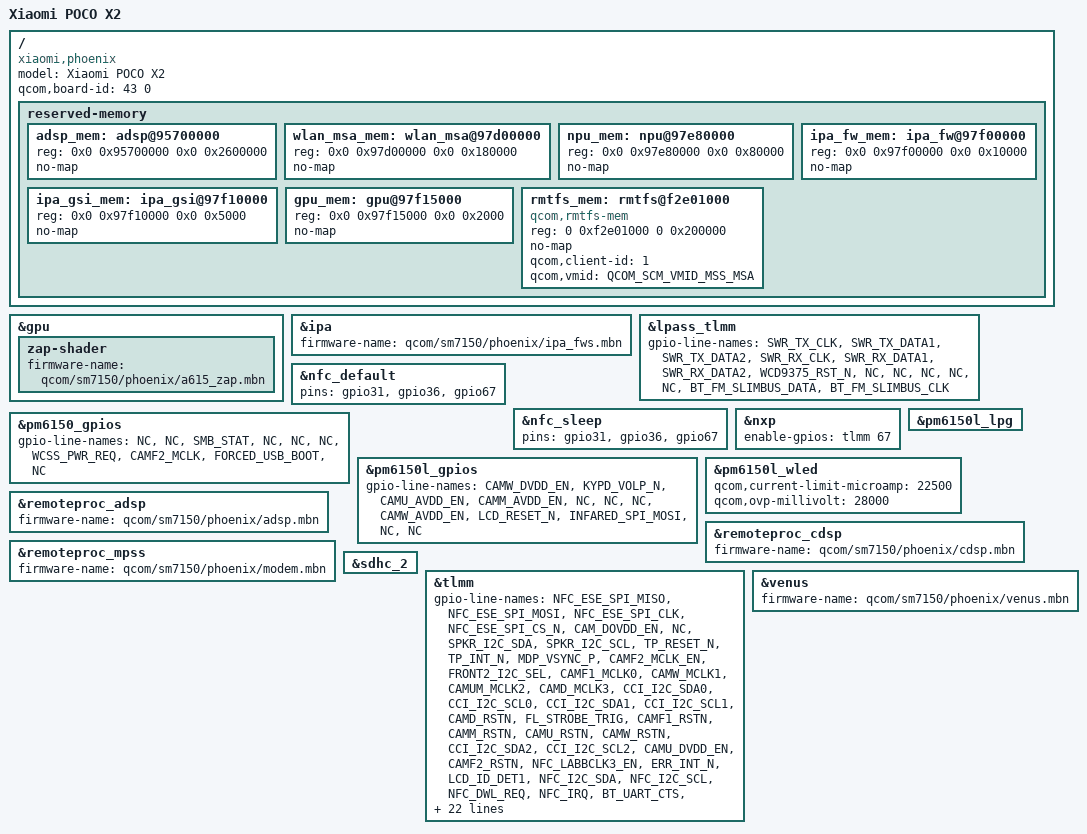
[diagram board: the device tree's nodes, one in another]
// SPDX-License-Identifier: BSD-3-Clause
/*
 * Copyright (c) 2024, Danila Tikhonov <danila@jiaxyga.com>
 */

/dts-v1/;

#include "sm7150-xiaomi-common.dtsi"

/delete-node/ &adsp_mem;
/delete-node/ &wlan_msa_mem;
/delete-node/ &npu_mem;
/delete-node/ &ipa_fw_mem;
/delete-node/ &ipa_gsi_mem;
/delete-node/ &gpu_mem;

/ {
	/*
	 * Xiaomi POCO X2
	 * Xiaomi Redmi K30 4G
	 */
	model = "Xiaomi POCO X2";
	compatible = "xiaomi,phoenix", "qcom,sm7150";

	qcom,board-id = <43 0>;

	reserved-memory {
		adsp_mem: adsp@95700000 {
			reg = <0x0 0x95700000 0x0 0x2600000>;
			no-map;
		};

		wlan_msa_mem: wlan_msa@97d00000 {
			reg = <0x0 0x97d00000 0x0 0x180000>;
			no-map;
		};

		npu_mem: npu@97e80000 {
			reg = <0x0 0x97e80000 0x0 0x80000>;
			no-map;
		};

		ipa_fw_mem: ipa_fw@97f00000 {
			reg = <0x0 0x97f00000 0x0 0x10000>;
			no-map;
		};

		ipa_gsi_mem: ipa_gsi@97f10000 {
			reg = <0x0 0x97f10000 0x0 0x5000>;
			no-map;
		};

		gpu_mem: gpu@97f15000 {
			reg = <0x0 0x97f15000 0x0 0x2000>;
			no-map;
		};

		rmtfs_mem: rmtfs@f2e01000 {
			compatible = "qcom,rmtfs-mem";
			reg = <0 0xf2e01000 0 0x200000>;
			no-map;

			qcom,client-id = <1>;
			qcom,vmid = <QCOM_SCM_VMID_MSS_MSA>;
		};
	};
};

&gpu {
	zap-shader {
		firmware-name = "qcom/sm7150/phoenix/a615_zap.mbn";
	};
};

&ipa {
	firmware-name = "qcom/sm7150/phoenix/ipa_fws.mbn";
};

&lpass_tlmm {
	gpio-line-names = "SWR_TX_CLK", /* GPIO_0 */
			  "SWR_TX_DATA1",
			  "SWR_TX_DATA2",
			  "SWR_RX_CLK",
			  "SWR_RX_DATA1",
			  "SWR_RX_DATA2",
			  "WCD9375_RST_N",
			  "NC",
			  "NC",
			  "NC",
			  "NC", /* GPIO_10 */
			  "NC",
			  "BT_FM_SLIMBUS_DATA",
			  "BT_FM_SLIMBUS_CLK";
};

&nfc_default {
	pins = "gpio31", "gpio36", "gpio67";
};

&nfc_sleep {
	pins = "gpio31", "gpio36", "gpio67";
};

&nxp {
	enable-gpios = <&tlmm 67 GPIO_ACTIVE_HIGH>;
};

&pm6150_gpios {
	gpio-line-names = "NC", /* GPIO_1 */
			  "NC",
			  "SMB_STAT",
			  "NC",
			  "NC",
			  "NC",
			  "WCSS_PWR_REQ",
			  "CAMF2_MCLK",
			  "FORCED_USB_BOOT",
			  "NC";  /* GPIO_10 */
};

&pm6150l_gpios {
	gpio-line-names = "CAMW_DVDD_EN", /* GPIO_1 */
			  "KYPD_VOLP_N",
			  "CAMU_AVDD_EN",
			  "CAMM_AVDD_EN",
			  "NC",
			  "NC",
			  "NC",
			  "CAMW_AVDD_EN",
			  "LCD_RESET_N",
			  "INFARED_SPI_MOSI", /* GPIO_10 */
			  "NC",
			  "NC";
};

&pm6150l_lpg {
	status = "okay";
};

&pm6150l_wled {
	qcom,current-limit-microamp = <22500>;
	qcom,ovp-millivolt = <28000>;

	status = "okay";
};

&remoteproc_adsp {
	firmware-name = "qcom/sm7150/phoenix/adsp.mbn";
};

&remoteproc_cdsp {
	firmware-name = "qcom/sm7150/phoenix/cdsp.mbn";
};

&remoteproc_mpss {
	firmware-name = "qcom/sm7150/phoenix/modem.mbn";
};

&sdhc_2 {
	status = "okay";
};

&tlmm {
	gpio-line-names = "NFC_ESE_SPI_MISO", /* GPIO_0 */
			  "NFC_ESE_SPI_MOSI",
			  "NFC_ESE_SPI_CLK",
			  "NFC_ESE_SPI_CS_N",
			  "CAM_DOVDD_EN",
			  "NC",
			  "SPKR_I2C_SDA",
			  "SPKR_I2C_SCL",
			  "TP_RESET_N",
			  "TP_INT_N",
			  "MDP_VSYNC_P", /* GPIO_10 */
			  "CAMF2_MCLK_EN",
			  "FRONT2_I2C_SEL",
			  "CAMF1_MCLK0",
			  "CAMW_MCLK1",
			  "CAMUM_MCLK2",
			  "CAMD_MCLK3",
			  "CCI_I2C_SDA0",
			  "CCI_I2C_SCL0",
			  "CCI_I2C_SDA1",
			  "CCI_I2C_SCL1", /* GPIO_20 */
			  "CAMD_RSTN",
			  "FL_STROBE_TRIG",
			  "CAMF1_RSTN",
			  "CAMM_RSTN",
			  "CAMU_RSTN",
			  "CAMW_RSTN",
			  "CCI_I2C_SDA2",
			  "CCI_I2C_SCL2",
			  "CAMU_DVDD_EN",
			  "CAMF2_RSTN",  /* GPIO_30 */
			  "NFC_LABBCLK3_EN",
			  "ERR_INT_N",
			  "LCD_ID_DET1",
			  "NFC_I2C_SDA",
			  "NFC_I2C_SCL",
			  "NFC_DWL_REQ",
			  "NFC_IRQ",
			  "BT_UART_CTS",
			  "BT_UART_RFR",
			  "BT_UART_TX", /* GPIO_40 */
			  "BT_UART_RX",
			  "NC",
			  "INFARED_SPI_MOSI",
			  "BLSP2_UART_TX",
			  "BLSP2_UART_RX",
			  "APPS_I2C_SDA",
			  "APPS_I2C_SCL",
			  "FORCED_USB_BOOT",
			  "SPKR_I2S_BCK",
			  "SPKR_I2S_WS", /* GPIO_50 */
			  "SPKR_I2S_DOUT",
			  "SPKR_I2S_DIN1",
			  "TP_SPI_MISO",
			  "TP_SPI_MOSI",
			  "TP_SPI_CLK",
			  "TP_SPI_CS",
			  "FP_INT_N",
			  "FP_RESET_N",
			  "FP_SPI_MISO",
			  "FP_SPI_MOSI", /* GPIO_60 */
			  "FP_SPI_CLK",
			  "FP_SPI_CS_N",
			  "FP_LDO_EN",
			  "CAMF2_TEST_INT",
			  "LCD_ID_DET2",
			  "SPKR_PA_RST",
			  "NFC_ENABLE",
			  "VBUS_DIS_EN",
			  "SD_CARD_DET_N",
			  "NC", /* GPIO_70 */
			  "NC",
			  "CAMF1_DVDD_AVDD_EN",
			  "WLAN_SW_CTRL",
			  "GRFC_4",
			  "UIM2_DATA",
			  "UIM2_CLK",
			  "UIM2_RESET",
			  "UIM2_PRESENT",
			  "UIM1_DATA",
			  "UIM1_CLK", /* GPIO_80 */
			  "UIM1_RESET",
			  "UIM1_PRESENT",
			  "NC",
			  "NC",
			  "WMSS_RESET_N",
			  "ACCEL_INT",
			  "GYRO_INT",
			  "MIPI_SEL",
			  "ALS_INT_N",
			  "PS_INT_N", /* GPIO_90 */
			  "SW_IO",
			  "RFFE4_CLK",
			  "SPKR_INT",
			  "CAMF2_INT",
			  "GRFC_3",
			  "QLINK_REQUEST",
			  "QLINK_ENABLE",
			  "GRFC_2",
			  "GRFC_0",
			  "GRFC_1", /* GPIO_100 */
			  "RFFE3_DATA",
			  "RFFE3_CLK",
			  "RFFE4_DATA",
			  "USB_PHY_PS",
			  "RFFE5_DATA",
			  "RFFE5_CLK",
			  "GRFC_5",
			  "WLAN_COEX_UART_TXD",
			  "WLAN_COEX_UART_RXD",
			  "NC", /* GPIO_110 */
			  "NC",
			  "RFFE1_DATA",
			  "RFFE1_CLK";
};

&venus {
	firmware-name = "qcom/sm7150/phoenix/venus.mbn";
};
